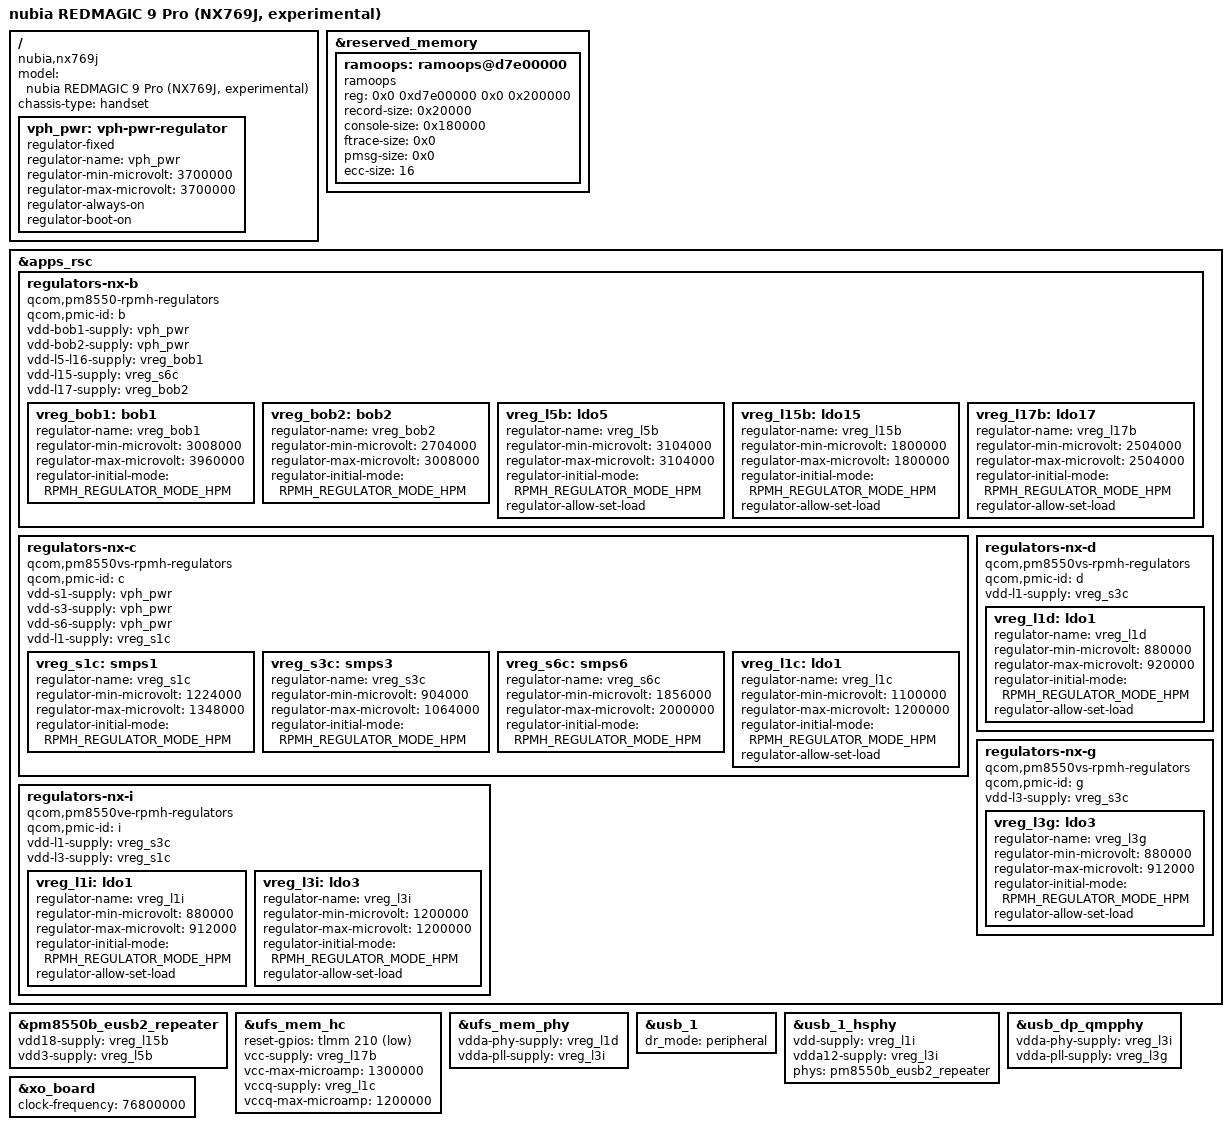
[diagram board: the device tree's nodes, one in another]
// SPDX-License-Identifier: BSD-3-Clause
/*
 * Red Magic 9 Pro (NX769J/tiro) mainline bring-up candidate.
 *
 * NOT BOOT-VALIDATED. This is a source build target, not a flashable board
 * description. UFS and USB wiring are inferred from a public, decompiled
 * NX769J vendor tree and checked against the SM8650 QRD bindings. That dump
 * does not establish that every NX769J SKU has the same hardware. In
 * particular the boot firmware's reserved-memory handoff has not been
 * validated. Display, touch, GPU, Wi-Fi, modem and audio are left disabled.
 * Never treat a successful dtc build as permission to boot this image.
 *
 * SM8650 SoC and QRD reference: Copyright (c) 2023, Linaro Limited.
 */

/dts-v1/;

#include <dt-bindings/gpio/gpio.h>
#include <dt-bindings/regulator/qcom,rpmh-regulator.h>
#include "sm8650.dtsi"
#include "pm8550.dtsi"
#include "pm8550b.dtsi"
#define PMK8550VE_SID 8
#include "pm8550ve.dtsi"
#include "pm8550vs.dtsi"
#include "pmk8550.dtsi"

/ {
	model = "nubia REDMAGIC 9 Pro (NX769J, experimental)";
	compatible = "nubia,nx769j", "qcom,sm8650";
	chassis-type = "handset";

	/* QRD boot-time supply model; electrical validation is still required. */
	vph_pwr: vph-pwr-regulator {
		compatible = "regulator-fixed";
		regulator-name = "vph_pwr";
		regulator-min-microvolt = <3700000>;
		regulator-max-microvolt = <3700000>;
		regulator-always-on;
		regulator-boot-on;
	};
};

&reserved_memory {
	/* Same 2 MiB region as stock ramoops/RAMCON. */
	ramoops: ramoops@d7e00000 {
		compatible = "ramoops";
		reg = <0x0 0xd7e00000 0x0 0x200000>;
		record-size = <0x20000>;
		console-size = <0x180000>;
		ftrace-size = <0x0>;
		pmsg-size = <0x0>;
		ecc-size = <16>;
	};
};

/* Supply IDs and voltage limits derived from the public NX769J stock DT. */
&apps_rsc {
	regulators-nx-b {
		compatible = "qcom,pm8550-rpmh-regulators";
		qcom,pmic-id = "b";
		vdd-bob1-supply = <&vph_pwr>;
		vdd-bob2-supply = <&vph_pwr>;
		vdd-l5-l16-supply = <&vreg_bob1>;
		vdd-l15-supply = <&vreg_s6c>;
		vdd-l17-supply = <&vreg_bob2>;

		vreg_bob1: bob1 {
			regulator-name = "vreg_bob1";
			regulator-min-microvolt = <3008000>;
			regulator-max-microvolt = <3960000>;
			regulator-initial-mode = <RPMH_REGULATOR_MODE_HPM>;
		};
		vreg_bob2: bob2 {
			regulator-name = "vreg_bob2";
			regulator-min-microvolt = <2704000>;
			regulator-max-microvolt = <3008000>;
			regulator-initial-mode = <RPMH_REGULATOR_MODE_HPM>;
		};
		vreg_l5b: ldo5 {
			regulator-name = "vreg_l5b";
			regulator-min-microvolt = <3104000>;
			regulator-max-microvolt = <3104000>;
			regulator-initial-mode = <RPMH_REGULATOR_MODE_HPM>;
			regulator-allow-set-load;
		};
		vreg_l15b: ldo15 {
			regulator-name = "vreg_l15b";
			regulator-min-microvolt = <1800000>;
			regulator-max-microvolt = <1800000>;
			regulator-initial-mode = <RPMH_REGULATOR_MODE_HPM>;
			regulator-allow-set-load;
		};
		vreg_l17b: ldo17 {
			regulator-name = "vreg_l17b";
			regulator-min-microvolt = <2504000>;
			regulator-max-microvolt = <2504000>;
			regulator-initial-mode = <RPMH_REGULATOR_MODE_HPM>;
			regulator-allow-set-load;
		};
	};

	regulators-nx-c {
		compatible = "qcom,pm8550vs-rpmh-regulators";
		qcom,pmic-id = "c";
		vdd-s1-supply = <&vph_pwr>;
		vdd-s3-supply = <&vph_pwr>;
		vdd-s6-supply = <&vph_pwr>;
		vdd-l1-supply = <&vreg_s1c>;
		vreg_s1c: smps1 {
			regulator-name = "vreg_s1c";
			regulator-min-microvolt = <1224000>;
			regulator-max-microvolt = <1348000>;
			regulator-initial-mode = <RPMH_REGULATOR_MODE_HPM>;
		};
		vreg_s3c: smps3 {
			regulator-name = "vreg_s3c";
			regulator-min-microvolt = <904000>;
			regulator-max-microvolt = <1064000>;
			regulator-initial-mode = <RPMH_REGULATOR_MODE_HPM>;
		};
		vreg_s6c: smps6 {
			regulator-name = "vreg_s6c";
			regulator-min-microvolt = <1856000>;
			regulator-max-microvolt = <2000000>;
			regulator-initial-mode = <RPMH_REGULATOR_MODE_HPM>;
		};
		vreg_l1c: ldo1 {
			regulator-name = "vreg_l1c";
			regulator-min-microvolt = <1100000>;
			regulator-max-microvolt = <1200000>;
			regulator-initial-mode = <RPMH_REGULATOR_MODE_HPM>;
			regulator-allow-set-load;
		};
	};

	regulators-nx-d {
		compatible = "qcom,pm8550vs-rpmh-regulators";
		qcom,pmic-id = "d";
		vdd-l1-supply = <&vreg_s3c>;
		vreg_l1d: ldo1 {
			regulator-name = "vreg_l1d";
			regulator-min-microvolt = <880000>;
			regulator-max-microvolt = <920000>;
			regulator-initial-mode = <RPMH_REGULATOR_MODE_HPM>;
			regulator-allow-set-load;
		};
	};

	regulators-nx-g {
		compatible = "qcom,pm8550vs-rpmh-regulators";
		qcom,pmic-id = "g";
		vdd-l3-supply = <&vreg_s3c>;
		vreg_l3g: ldo3 {
			regulator-name = "vreg_l3g";
			regulator-min-microvolt = <880000>;
			regulator-max-microvolt = <912000>;
			regulator-initial-mode = <RPMH_REGULATOR_MODE_HPM>;
			regulator-allow-set-load;
		};
	};

	regulators-nx-i {
		compatible = "qcom,pm8550ve-rpmh-regulators";
		qcom,pmic-id = "i";
		vdd-l1-supply = <&vreg_s3c>;
		vdd-l3-supply = <&vreg_s1c>;
		vreg_l1i: ldo1 {
			regulator-name = "vreg_l1i";
			regulator-min-microvolt = <880000>;
			regulator-max-microvolt = <912000>;
			regulator-initial-mode = <RPMH_REGULATOR_MODE_HPM>;
			regulator-allow-set-load;
		};
		vreg_l3i: ldo3 {
			regulator-name = "vreg_l3i";
			regulator-min-microvolt = <1200000>;
			regulator-max-microvolt = <1200000>;
			regulator-initial-mode = <RPMH_REGULATOR_MODE_HPM>;
			regulator-allow-set-load;
		};
	};
};

&pm8550b_eusb2_repeater {
	vdd18-supply = <&vreg_l15b>;
	vdd3-supply = <&vreg_l5b>;
};

/* Stock DT: ufshc@1d84000, reset TLMM GPIO 210, ldob17/ldoc1 supplies. */
&ufs_mem_hc {
	reset-gpios = <&tlmm 210 GPIO_ACTIVE_LOW>;
	vcc-supply = <&vreg_l17b>;
	vcc-max-microamp = <1300000>;
	vccq-supply = <&vreg_l1c>;
	vccq-max-microamp = <1200000>;
	status = "okay";
};

&ufs_mem_phy {
	vdda-phy-supply = <&vreg_l1d>;
	vdda-pll-supply = <&vreg_l3i>;
	status = "okay";
};

/* Unverified fixed peripheral mode, intended for future USB/SSH bring-up. */
&usb_1 {
	dr_mode = "peripheral";
	status = "okay";
};

&usb_1_hsphy {
	vdd-supply = <&vreg_l1i>;
	vdda12-supply = <&vreg_l3i>;
	phys = <&pm8550b_eusb2_repeater>;
	status = "okay";
};

&usb_dp_qmpphy {
	vdda-phy-supply = <&vreg_l3i>;
	vdda-pll-supply = <&vreg_l3g>;
	status = "okay";
};

&xo_board {
	clock-frequency = <76800000>;
};
